AUTOSAR XML (schema 4-0-3)
package /ComponentTypes
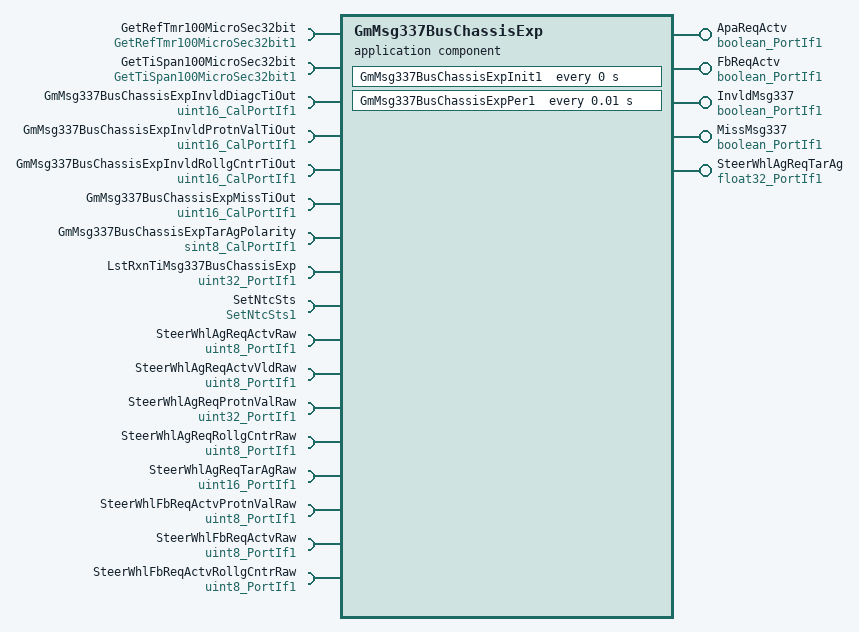
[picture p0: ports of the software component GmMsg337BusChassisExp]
  application sw component type GmMsg337BusChassisExp
    5 x provide port:
      ApaReqActv: nonqueued-sender-com-spec{data-element=Logl, init-value=0}, provided-interface=boolean_PortIf1
      FbReqActv: nonqueued-sender-com-spec{data-element=Logl, init-value=0}, provided-interface=boolean_PortIf1
      InvldMsg337: nonqueued-sender-com-spec{data-element=Logl, init-value=0}, provided-interface=boolean_PortIf1
      MissMsg337: nonqueued-sender-com-spec{data-element=Logl, init-value=0}, provided-interface=boolean_PortIf1
      SteerWhlAgReqTarAg: nonqueued-sender-com-spec{data-element=Val, init-value=0}, provided-interface=float32_PortIf1
    17 x require port:
      GetRefTmr100MicroSec32bit: required-interface=GetRefTmr100MicroSec32bit1
      GetTiSpan100MicroSec32bit: required-interface=GetTiSpan100MicroSec32bit1
      GmMsg337BusChassisExpInvldDiagcTiOut: parameter-require-com-spec{init-value=500, parameter=Val}, required-interface=uint16_CalPortIf1
      GmMsg337BusChassisExpInvldProtnValTiOut: parameter-require-com-spec{init-value=5, parameter=Val}, required-interface=uint16_CalPortIf1
      GmMsg337BusChassisExpInvldRollgCntrTiOut: parameter-require-com-spec{init-value=5, parameter=Val}, required-interface=uint16_CalPortIf1
      GmMsg337BusChassisExpMissTiOut: parameter-require-com-spec{init-value=1000, parameter=Val}, required-interface=uint16_CalPortIf1
      GmMsg337BusChassisExpTarAgPolarity: parameter-require-com-spec{init-value=1, parameter=Val}, required-interface=sint8_CalPortIf1
      LstRxnTiMsg337BusChassisExp: nonqueued-receiver-com-spec{data-element=Val, filter=data-filter-type=ALWAYS, init-value=0}, required-interface=uint32_PortIf1
      SetNtcSts: required-interface=SetNtcSts1
      SteerWhlAgReqActvRaw: nonqueued-receiver-com-spec{data-element=Val, filter=data-filter-type=ALWAYS, init-value=0}, required-interface=uint8_PortIf1
      SteerWhlAgReqActvVldRaw: nonqueued-receiver-com-spec{data-element=Val, filter=data-filter-type=ALWAYS, init-value=0}, required-interface=uint8_PortIf1
      SteerWhlAgReqProtnValRaw: nonqueued-receiver-com-spec{data-element=Val, filter=data-filter-type=ALWAYS, init-value=0}, required-interface=uint32_PortIf1
      SteerWhlAgReqRollgCntrRaw: nonqueued-receiver-com-spec{data-element=Val, filter=data-filter-type=ALWAYS, init-value=0}, required-interface=uint8_PortIf1
      SteerWhlAgReqTarAgRaw: nonqueued-receiver-com-spec{data-element=Val, filter=data-filter-type=ALWAYS, init-value=0}, required-interface=uint16_PortIf1
      SteerWhlFbReqActvProtnValRaw: nonqueued-receiver-com-spec{data-element=Val, filter=data-filter-type=ALWAYS, init-value=0}, required-interface=uint8_PortIf1
      SteerWhlFbReqActvRaw: nonqueued-receiver-com-spec{data-element=Val, filter=data-filter-type=ALWAYS, init-value=0}, required-interface=uint8_PortIf1
      SteerWhlFbReqActvRollgCntrRaw: nonqueued-receiver-com-spec{data-element=Val, filter=data-filter-type=ALWAYS, init-value=0}, required-interface=uint8_PortIf1
    behavior GmMsg337BusChassisExp_InternalBehavior: data-type-mapping=Nexteer
      ar-typed-per-instance-memorys:
        10 x data, all with sw-calibration-access=READ-ONLY:
          GmMsg337BusChassisExpAgReqProtnValInvldTmr: type=uint32
          GmMsg337BusChassisExpAgReqRollgCntrInvldTmr: type=uint32
          GmMsg337BusChassisExpFbProtnValInvldTmr: type=uint32
          GmMsg337BusChassisExpFbRollgCntrInvldTmr: type=uint32
          GmMsg337BusChassisExpInvldTmr: type=uint32
          GmMsg337BusChassisExpPrevAgReqRollgCntVal: type=uint8
          GmMsg337BusChassisExpPrevFbReqRollgCntVal: type=uint8
          GmMsg337BusChassisExpPrevInvld: type=boolean
          GmMsg337BusChassisExpPrevRxnTi: type=uint32
          GmMsg337BusChassisExpRollgCntrRst: type=boolean
      timing event GmMsg337BusChassisExp_InitEvent: start-on-event=GmMsg337BusChassisExpInit1, period=0
      timing event TMT_GM0C9HSPer1: start-on-event=GmMsg337BusChassisExpPer1, period=0.01
      runnable GmMsg337BusChassisExpInit1
      runnable GmMsg337BusChassisExpPer1
        data-receive-point-by-arguments:
          9 x access:
            REC_Msg0C9HSLstRxnTi_Val: accessed-variable=LstRxnTiMsg337BusChassisExp.Val
            REC_SteerWhlAgReqActvRaw_Val: accessed-variable=SteerWhlAgReqActvRaw.Val
            REC_SteerWhlAgReqActvVldRaw_Val: accessed-variable=SteerWhlAgReqActvVldRaw.Val
            REC_SteerWhlAgReqProtnValRaw_Val: accessed-variable=SteerWhlAgReqProtnValRaw.Val
            REC_SteerWhlAgReqRollgCntrRaw_Val: accessed-variable=SteerWhlAgReqRollgCntrRaw.Val
            REC_SteerWhlAgReqTarAgRaw_Val: accessed-variable=SteerWhlAgReqTarAgRaw.Val
            REC_SteerWhlFdReqActvProtnValRaw_Val: accessed-variable=SteerWhlFbReqActvProtnValRaw.Val
            REC_SteerWhlFdReqActvRaw_Val: accessed-variable=SteerWhlFbReqActvRaw.Val
            REC_SteerWhlFdReqActvRollgCntrRaw_Val: accessed-variable=SteerWhlFbReqActvRollgCntrRaw.Val
        data-send-points:
          5 x access:
            SEND_ApaReqActv_Logl: accessed-variable=ApaReqActv.Logl
            SEND_FbReqActv_Logl: accessed-variable=FbReqActv.Logl
            SEND_InvldMsg337_Logl: accessed-variable=InvldMsg337.Logl
            SEND_MissMsg337_Logl: accessed-variable=MissMsg337.Logl
            SEND_SteerWhlAgReqTarAg_Val: accessed-variable=SteerWhlAgReqTarAg.Val
        sync call SC_GetRefTmr100MicroSec32bit_Oper: operation=GetRefTmr100MicroSec32bit.Oper, timeout=0
        sync call SC_GetTiSpan100MicroSec32bit_Oper: operation=GetTiSpan100MicroSec32bit.Oper, timeout=0
        sync call SC_SetNtcSts_Oper: operation=SetNtcSts.Oper, timeout=0
  swc implementation GmMsg337BusChassisExp_Implementation: behavior=GmMsg337BusChassisExp_InternalBehavior
    code-descriptors:
      code Default: artifact-descriptors=autosar-engineering-object={short-label=Default, category=SWSRC}
